# MKV56F22 register map
Vendor: Freescale Semiconductor, Inc.; Series: Kinetis_V; File version: 1.6
CPU: CM7 r0p1, little endian, no MPU, FPU, VTOR, 4 interrupt priority bits
Registers are 32-bit, read-write, reset 0x0 unless marked. A register's access mark holds for its fields unless they carry their own. Offsets are from the block's base; [hi:lo] are bit positions; {n}, {i} and the like mark numbered series; 'fields as' and 'values as' point back to an identical list.

## XBARA — Crossbar Switch
Base 0x40059000; register names take the prefix XBARA_
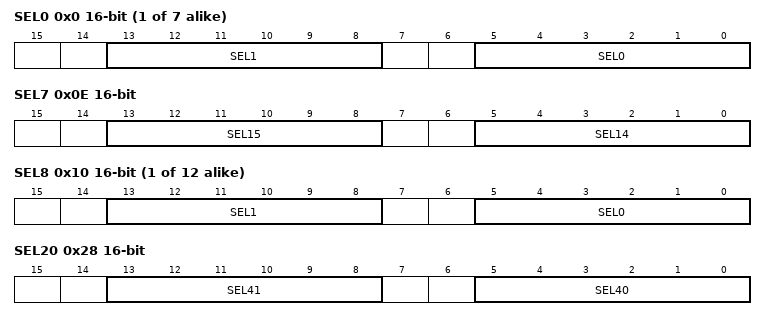
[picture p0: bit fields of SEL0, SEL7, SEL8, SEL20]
{0x0+2i} SEL{i} 16-bit (i=0..6) — Crossbar A Select Register {i}
  [13:8] SEL{2i+1} — Input (XBARA_INn) to be muxed to XBARA_OUT{2i+1} (refer to Functional Description section for input/output assignment)
    0=Logic zero; 1=Logic one; {v}=XBAR0_IN{v} input pin (v=2..11); {v}=CMP{v-12} Output (v=12..15); 16=FTM0 all channels output compare ORed together; 17=FTM0 all channels counter init ORed together; 18=FTM3 all channels output compare ORed together; 19=FTM3 all channels counter init ORed together; 20=PWMA channel 0 trigger 0; 21=PWMA channel 0 trigger 1; 22=PWMA channel 1 trigger 0; 23=PWMA channel 1 trigger 1; 24=PWMA channel 2 trigger 0; 25=PWMA channel 2 trigger 1; 26=PWMA channel 3 trigger 0; 27=PWMA channel 3 trigger 1; 28=PDB0 channel 1 output trigger; 29=PDB0 channel 0 output trigger; 30=PDB1 channel 1 output trigger; 31=PDB1 channel 0 output trigger; 32=High Speed Analog-to-Digital Converter 1 conversion A complete; 33=High Speed Analog-to-Digital Converter 0 conversion A complete; 34=High Speed Analog-to-Digital Converter 1 conversion B complete; 35=High Speed Analog-to-Digital Converter 0 conversion B complete; 36=FTM1 all channels output compare ORed together; 37=FTM1 all channels counter init ORed together; 38=DMA channel 0 done; 39=DMA channel 1 done; 40=DMA channel 6 done; 41=DMA channel 7 done; 42=PIT trigger 0; 43=PIT trigger 1; 44=Analog-to-Digital Converter 0 conversion complete; 45=ENC compare trigger and position match; {v}=AOI output {v-46} (v=46..49); 50=PIT trigger 2; 51=PIT trigger 3; {v}=PWMB channel {v-52} trigger 0 or trigger 1 (v=52..55); 56=FTM2 all channels output compare ORed together; 57=FTM2 all channels counter init ORed together
  [5:0] SEL{2i} — Input (XBARA_INn) to be muxed to XBARA_OUT{2i} (refer to Functional Description section for input/output assignment)
    values as SEL{2i+1}
0x0E SEL7 16-bit — Crossbar A Select Register 7
  [13:8] SEL15 — Input (XBARA_INn) to be muxed to XBARA_OUT15 (refer to Functional Description section for input/output assignment)
    values as SEL0.SEL{2i+1}
  [5:0] SEL14 — Input (XBARA_INn) to be muxed to XBARA_OUT14 (refer to Functional Description section for input/output assignment)
{0x0+2i} SEL{i} 16-bit (i=8..19) — Crossbar A Select Register {i}
  fields as SEL0
0x28 SEL20 16-bit — Crossbar A Select Register 20
  [13:8] SEL41 — Input (XBARA_INn) to be muxed to XBARA_OUT41 (refer to Functional Description section for input/output assignment)
    values as SEL0.SEL{2i+1}
  [5:0] SEL40 — Input (XBARA_INn) to be muxed to XBARA_OUT40 (refer to Functional Description section for input/output assignment)
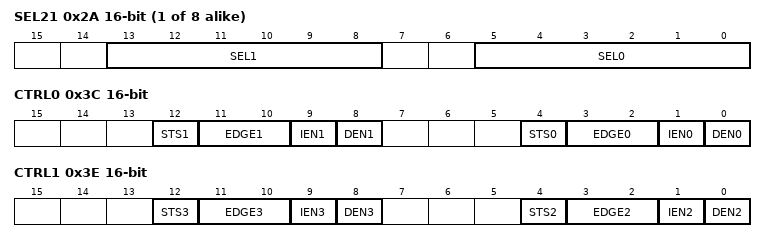
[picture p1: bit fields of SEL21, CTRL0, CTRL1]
{0x0+2i} SEL{i} 16-bit (i=21..28) — Crossbar A Select Register {i}
  fields as SEL0
0x3A SEL29 16-bit — Crossbar A Select Register 29
  [5:0] SEL58 — Input (XBARA_INn) to be muxed to XBARA_OUT58 (refer to Functional Description section for input/output assignment)
    values as SEL0.SEL{2i+1}
0x3C CTRL0 16-bit — Crossbar A Control Register 0
  [12] STS1 — Edge detection status for XBAR_OUT1
    0=Active edge not yet detected on XBAR_OUT1; 1=Active edge detected on XBAR_OUT1
  [11:10] EDGE1 — Active edge for edge detection on XBAR_OUT1
    0=STS1 never asserts; 1=STS1 asserts on rising edges of XBAR_OUT1; 2=STS1 asserts on falling edges of XBAR_OUT1; 3=STS1 asserts on rising and falling edges of XBAR_OUT1
  [9] IEN1 — Interrupt Enable for XBAR_OUT1
    0=Interrupt disabled; 1=Interrupt enabled
  [8] DEN1 — DMA Enable for XBAR_OUT1
    0=DMA disabled; 1=DMA enabled
  [4] STS0 — Edge detection status for XBAR_OUT0
    0=Active edge not yet detected on XBAR_OUT0; 1=Active edge detected on XBAR_OUT0
  [3:2] EDGE0 — Active edge for edge detection on XBAR_OUT0
    0=STS0 never asserts; 1=STS0 asserts on rising edges of XBAR_OUT0; 2=STS0 asserts on falling edges of XBAR_OUT0; 3=STS0 asserts on rising and falling edges of XBAR_OUT0
  [1] IEN0 — Interrupt Enable for XBAR_OUT0
    0=Interrupt disabled; 1=Interrupt enabled
  [0] DEN0 — DMA Enable for XBAR_OUT0
    0=DMA disabled; 1=DMA enabled
0x3E CTRL1 16-bit — Crossbar A Control Register 1
  [12] STS3 — Edge detection status for XBAR_OUT3
    0=Active edge not yet detected on XBAR_OUT3; 1=Active edge detected on XBAR_OUT3
  [11:10] EDGE3 — Active edge for edge detection on XBAR_OUT3
    0=STS3 never asserts; 1=STS3 asserts on rising edges of XBAR_OUT3; 2=STS3 asserts on falling edges of XBAR_OUT3; 3=STS3 asserts on rising and falling edges of XBAR_OUT3
  [9] IEN3 — Interrupt Enable for XBAR_OUT3
    0=Interrupt disabled; 1=Interrupt enabled
  [8] DEN3 — DMA Enable for XBAR_OUT3
    0=DMA disabled; 1=DMA enabled
  [4] STS2 — Edge detection status for XBAR_OUT2
    0=Active edge not yet detected on XBAR_OUT2; 1=Active edge detected on XBAR_OUT2
  [3:2] EDGE2 — Active edge for edge detection on XBAR_OUT2
    0=STS2 never asserts; 1=STS2 asserts on rising edges of XBAR_OUT2; 2=STS2 asserts on falling edges of XBAR_OUT2; 3=STS2 asserts on rising and falling edges of XBAR_OUT2
  [1] IEN2 — Interrupt Enable for XBAR_OUT2
    0=Interrupt disabled; 1=Interrupt enabled
  [0] DEN2 — DMA Enable for XBAR_OUT2
    0=DMA disabled; 1=DMA enabled
